# EFM32GG11B420F2048IL120 register map
File version: 4.0.0
CPU: CM4 r0p1, little endian, MPU, FPU, 3 interrupt priority bits
Registers are 32-bit, read-write, reset 0x0 unless marked. A register's access mark holds for its fields unless they carry their own. Offsets are from the block's base; [hi:lo] are bit positions; {n}, {i} and the like mark numbered series.

## LEUART0
Base 0x4006A000
Same registers: LEUART1 0x4006A400
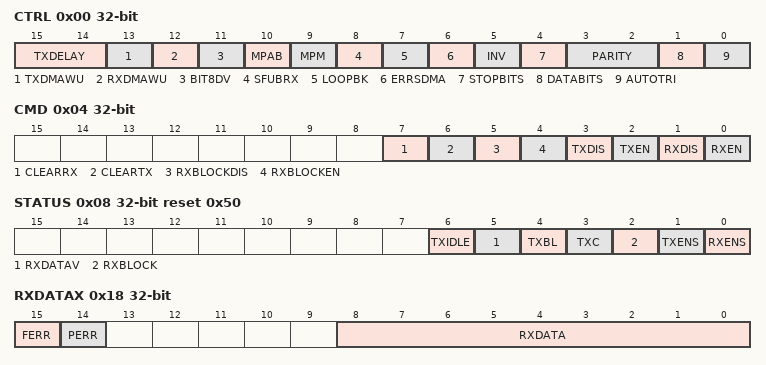
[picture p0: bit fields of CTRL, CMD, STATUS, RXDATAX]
0x00 CTRL — Control Register
  [15:14] TXDELAY — TX Delay Transmission
    0=NONE (Frames are transmitted immediately); 1=SINGLE (Transmission of new frames are delayed by a single bit period); 2=DOUBLE (Transmission of new frames are delayed by two bit periods); 3=TRIPLE (Transmission of new frames are delayed by three bit periods)
  [13] TXDMAWU — TX DMA Wakeup
  [12] RXDMAWU — RX DMA Wakeup
  [11] BIT8DV — Bit 8 Default Value
  [10] MPAB — Multi-Processor Address-Bit
  [9] MPM — Multi-Processor Mode
  [8] SFUBRX — Start-Frame UnBlock RX
  [7] LOOPBK — Loopback Enable
  [6] ERRSDMA — Clear RX DMA on Error
  [5] INV — Invert Input and Output
  [4] STOPBITS — Stop-Bit Mode
  [3:2] PARITY — Parity-Bit Mode
    0=NONE (Parity bits are not used); 2=EVEN (Even parity are used. Parity bits are automatically generated and checked by hardware.); 3=ODD (Odd parity is used. Parity bits are automatically generated and checked by hardware.)
  [1] DATABITS — Data-Bit Mode
  [0] AUTOTRI — Automatic Transmitter Tristate
0x04 CMD wo — Command Register
  [7] CLEARRX
  [6] CLEARTX
  [5] RXBLOCKDIS — Receiver Block Disable
  [4] RXBLOCKEN — Receiver Block Enable
  [3] TXDIS — Transmitter Disable
  [2] TXEN — Transmitter Enable
  [1] RXDIS — Receiver Disable
  [0] RXEN — Receiver Enable
0x08 STATUS ro reset 0x50
  [6] TXIDLE
  [5] RXDATAV — RX Data Valid
  [4] TXBL — TX Buffer Level
  [3] TXC — TX Complete
  [2] RXBLOCK — Block Incoming Data
  [1] TXENS — Transmitter Enable Status
  [0] RXENS — Receiver Enable Status
0x0C CLKDIV — Clock Control Register
  [16:3] DIV — Fractional Clock Divider
0x10 STARTFRAME
  [8:0] STARTFRAME
0x14 SIGFRAME — Signal Frame Register
  [8:0] SIGFRAME — Signal Frame
0x18 RXDATAX ro read-has-side-effects — Receive Buffer Data Extended Register
  [15] FERR — Receive Data Framing Error
  [14] PERR — Receive Data Parity Error
  [8:0] RXDATA
0x1C RXDATA ro read-has-side-effects — Receive Buffer Data Register
  [7:0] RXDATA
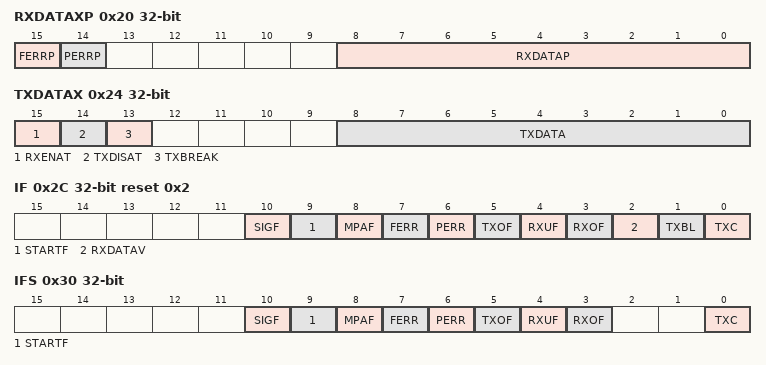
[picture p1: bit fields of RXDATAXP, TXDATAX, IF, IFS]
0x20 RXDATAXP ro — Receive Buffer Data Extended Peek Register
  [15] FERRP — Receive Data Framing Error Peek
  [14] PERRP — Receive Data Parity Error Peek
  [8:0] RXDATAP — RX Data Peek
0x24 TXDATAX — Transmit Buffer Data Extended Register
  [15] RXENAT — Enable RX After Transmission
  [14] TXDISAT — Disable TX After Transmission
  [13] TXBREAK — Transmit Data as Break
  [8:0] TXDATA
0x28 TXDATA — Transmit Buffer Data Register
  [7:0] TXDATA
0x2C IF ro reset 0x2 — Interrupt Flag Register
  [10] SIGF — Signal Frame Interrupt Flag
  [9] STARTF — Start Frame Interrupt Flag
  [8] MPAF — Multi-Processor Address Frame Interrupt Flag
  [7] FERR — Framing Error Interrupt Flag
  [6] PERR — Parity Error Interrupt Flag
  [5] TXOF — TX Overflow Interrupt Flag
  [4] RXUF — RX Underflow Interrupt Flag
  [3] RXOF — RX Overflow Interrupt Flag
  [2] RXDATAV — RX Data Valid Interrupt Flag
  [1] TXBL — TX Buffer Level Interrupt Flag
  [0] TXC — TX Complete Interrupt Flag
0x30 IFS wo — Interrupt Flag Set Register
  [10] SIGF — Set SIGF Interrupt Flag
  [9] STARTF — Set STARTF Interrupt Flag
  [8] MPAF — Set MPAF Interrupt Flag
  [7] FERR — Set FERR Interrupt Flag
  [6] PERR — Set PERR Interrupt Flag
  [5] TXOF — Set TXOF Interrupt Flag
  [4] RXUF — Set RXUF Interrupt Flag
  [3] RXOF — Set RXOF Interrupt Flag
  [0] TXC — Set TXC Interrupt Flag
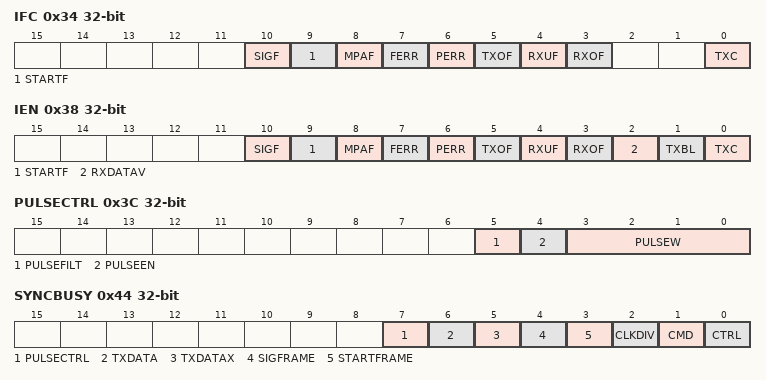
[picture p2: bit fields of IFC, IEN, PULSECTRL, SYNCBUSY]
0x34 IFC wo — Interrupt Flag Clear Register
  [10] SIGF — Clear SIGF Interrupt Flag
  [9] STARTF — Clear STARTF Interrupt Flag
  [8] MPAF — Clear MPAF Interrupt Flag
  [7] FERR — Clear FERR Interrupt Flag
  [6] PERR — Clear PERR Interrupt Flag
  [5] TXOF — Clear TXOF Interrupt Flag
  [4] RXUF — Clear RXUF Interrupt Flag
  [3] RXOF — Clear RXOF Interrupt Flag
  [0] TXC — Clear TXC Interrupt Flag
0x38 IEN — Interrupt Enable Register
  [10] SIGF — SIGF Interrupt Enable
  [9] STARTF — STARTF Interrupt Enable
  [8] MPAF — MPAF Interrupt Enable
  [7] FERR — FERR Interrupt Enable
  [6] PERR — PERR Interrupt Enable
  [5] TXOF — TXOF Interrupt Enable
  [4] RXUF — RXUF Interrupt Enable
  [3] RXOF — RXOF Interrupt Enable
  [2] RXDATAV — RXDATAV Interrupt Enable
  [1] TXBL — TXBL Interrupt Enable
  [0] TXC — TXC Interrupt Enable
0x3C PULSECTRL — Pulse Control Register
  [5] PULSEFILT — Pulse Filter
  [4] PULSEEN — Pulse Generator/Extender Enable
  [3:0] PULSEW — Pulse Width
0x40 FREEZE
  [0] REGFREEZE — Register Update Freeze
0x44 SYNCBUSY ro — Synchronization Busy Register
  [7] PULSECTRL — PULSECTRL Register Busy
  [6] TXDATA — TXDATA Register Busy
  [5] TXDATAX — TXDATAX Register Busy
  [4] SIGFRAME — SIGFRAME Register Busy
  [3] STARTFRAME — STARTFRAME Register Busy
  [2] CLKDIV — CLKDIV Register Busy
  [1] CMD — CMD Register Busy
  [0] CTRL — CTRL Register Busy
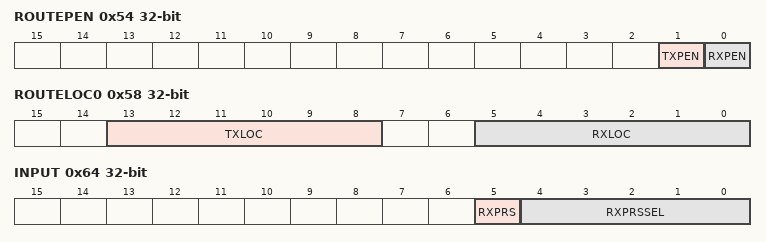
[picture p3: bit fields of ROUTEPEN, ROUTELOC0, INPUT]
0x54 ROUTEPEN — I/O Routing Pin Enable Register
  [1] TXPEN — TX Pin Enable
  [0] RXPEN — RX Pin Enable
0x58 ROUTELOC0 — I/O Routing Location Register
  [13:8] TXLOC — I/O Location
    {v}=LOC{v} (Location {v}) (v=0..5)
  [5:0] RXLOC — I/O Location
    {v}=LOC{v} (Location {v}) (v=0..5)
0x64 INPUT — LEUART Input Register
  [5] RXPRS — PRS RX Enable
  [4:0] RXPRSSEL — RX PRS Channel Select
    {v}=PRSCH{v} (PRS Channel {v} selected) (v=0..23)

## Notices in the file
# License
Copyright 2021 Silicon Laboratories Inc. www.silabs.com
SPDX-License-Identifier: Zlib
The licensor of this software is Silicon Laboratories Inc.
This software is provided 'as-is', without any express or implied
warranty. In no event will the authors be held liable for any damages
arising from the use of this software.
Permission is granted to anyone to use this software for any purpose,
including commercial applications, and to alter it and redistribute it
freely, subject to the following restrictions:
1. The origin of this software must not be misrepresented; you must not
claim that you wrote the original software. If you use this software
in a product, an acknowledgment in the product documentation would be
appreciated but is not required.
2. Altered source versions must be plainly marked as such, and must not be
misrepresented as being the original software.
3. This notice may not be removed or altered from any source distribution.
